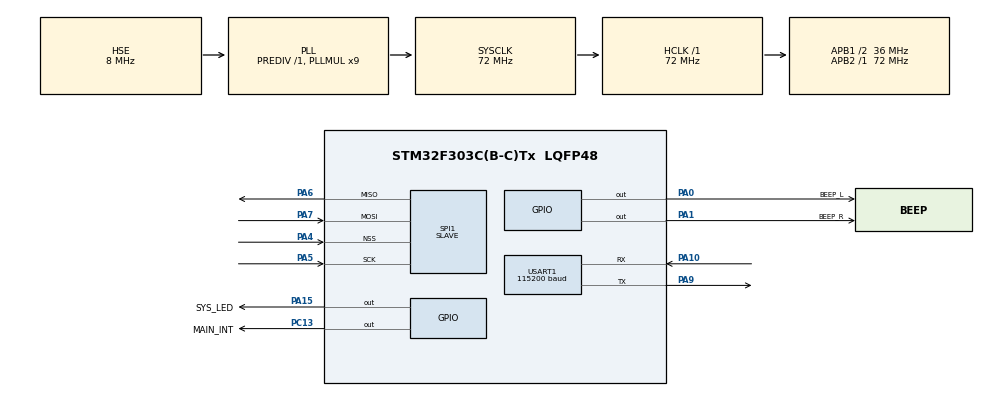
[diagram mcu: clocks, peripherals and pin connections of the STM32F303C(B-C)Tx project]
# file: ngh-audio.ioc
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Mcu.Family=STM32F3
Mcu.Name=STM32F303C(B-C)Tx
Mcu.Package=LQFP48
NVIC.PriorityGroup=NVIC_PRIORITYGROUP_4
NVIC.SPI1_IRQn=true\:1\:0\:true\:false\:true\:true
NVIC.TIM2_IRQn=true\:0\:0\:false\:false\:true\:true
PA0.GPIO_Label=BEEP_L
PA0.Signal=GPIO_Output
PA1.GPIO_Label=BEEP_R
PA1.Signal=GPIO_Output
PA10.GPIO_PuPd=GPIO_PULLUP
PA10.Mode=Multiprocessor_communication
PA10.Signal=USART1_RX
PA13.Mode=Serial_Wire
PA13.Signal=SYS_JTMS-SWDIO
PA14.Mode=Serial_Wire
PA14.Signal=SYS_JTCK-SWCLK
PA15.GPIO_Label=SYS_LED
PA15.GPIO_Speed=GPIO_SPEED_FREQ_HIGH
PA15.Signal=GPIO_Output
PA4.Mode=NSS_Signal_Hard_Input
PA4.Signal=SPI1_NSS
PA5.Mode=Full_Duplex_Slave
PA5.Signal=SPI1_SCK
PA6.Mode=Full_Duplex_Slave
PA6.Signal=SPI1_MISO
PA7.Mode=Full_Duplex_Slave
PA7.Signal=SPI1_MOSI
PA9.GPIO_PuPd=GPIO_PULLUP
PA9.Mode=Multiprocessor_communication
PA9.Signal=USART1_TX
PC13.GPIO_Label=MAIN_INT
PC13.GPIO_Speed=GPIO_SPEED_FREQ_LOW
PC13.PinState=GPIO_PIN_SET
PC13.Signal=GPIO_Output
PF0-OSC_IN.Mode=HSE-External-Oscillator
PF0-OSC_IN.Signal=RCC_OSC_IN
PF1-OSC_OUT.Mode=HSE-External-Oscillator
PF1-OSC_OUT.Signal=RCC_OSC_OUT
ProjectManager.HeapSize=0x200
ProjectManager.StackSize=0x400
ProjectManager.TargetToolchain=SW4STM32
RCC.AHBFreq_Value=72000000
RCC.APB1CLKDivider=RCC_HCLK_DIV2
RCC.APB1Freq_Value=36000000
RCC.APB1TimFreq_Value=72000000
RCC.APB2Freq_Value=72000000
RCC.APB2TimFreq_Value=72000000
RCC.CortexFreq_Value=72000000
RCC.HCLKFreq_Value=72000000
RCC.HSE_VALUE=8000000
RCC.HSI_VALUE=8000000
RCC.LSE_VALUE=32768
RCC.PLLMUL=RCC_PLL_MUL9
RCC.PLLSourceVirtual=RCC_PLLSOURCE_HSE
RCC.SYSCLKFreq_VALUE=72000000
RCC.SYSCLKSourceVirtual=RCC_SYSCLKSOURCE_PLLCLK
RCC.USBFreq_Value=72000000
SPI1.DataSize=SPI_DATASIZE_8BIT
SPI1.Direction=SPI_DIRECTION_2LINES
SPI1.Mode=SPI_MODE_SLAVE
SPI1.VirtualNSS=VM_NSSHARD
SPI1.VirtualType=VM_SLAVE
TIM2.Period=99
TIM2.Prescaler=72
USART1.BaudRate=115200
USART1.VirtualMode-Multiprocessor_communication=VM_ASYNC
VP_TIM2_VS_ClockSourceINT.Mode=Internal
board=custom

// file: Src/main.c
/* USER CODE BEGIN Header */
/**
  ******************************************************************************
  * @file           : main.c
  * @brief          : Main program body
  ******************************************************************************
  ** This notice applies to any and all portions of this file
  * that are not between comment pairs USER CODE BEGIN and
  * USER CODE END. Other portions of this file, whether
  * inserted by the user or by software development tools
  * are owned by their respective copyright owners.
  *
  * COPYRIGHT(c) 2018 STMicroelectronics
  *
  * Redistribution and use in source and binary forms, with or without modification,
  * are permitted provided that the following conditions are met:
  *   1. Redistributions of source code must retain the above copyright notice,
  *      this list of conditions and the following disclaimer.
  *   2. Redistributions in binary form must reproduce the above copyright notice,
  *      this list of conditions and the following disclaimer in the documentation
  *      and/or other materials provided with the distribution.
  *   3. Neither the name of STMicroelectronics nor the names of its contributors
  *      may be used to endorse or promote products derived from this software
  *      without specific prior written permission.
  *
  * THIS SOFTWARE IS PROVIDED BY THE COPYRIGHT HOLDERS AND CONTRIBUTORS "AS IS"
  * AND ANY EXPRESS OR IMPLIED WARRANTIES, INCLUDING, BUT NOT LIMITED TO, THE
  * IMPLIED WARRANTIES OF MERCHANTABILITY AND FITNESS FOR A PARTICULAR PURPOSE ARE
  * DISCLAIMED. IN NO EVENT SHALL THE COPYRIGHT HOLDER OR CONTRIBUTORS BE LIABLE
  * FOR ANY DIRECT, INDIRECT, INCIDENTAL, SPECIAL, EXEMPLARY, OR CONSEQUENTIAL
  * DAMAGES (INCLUDING, BUT NOT LIMITED TO, PROCUREMENT OF SUBSTITUTE GOODS OR
  * SERVICES; LOSS OF USE, DATA, OR PROFITS; OR BUSINESS INTERRUPTION) HOWEVER
  * CAUSED AND ON ANY THEORY OF LIABILITY, WHETHER IN CONTRACT, STRICT LIABILITY,
  * OR TORT (INCLUDING NEGLIGENCE OR OTHERWISE) ARISING IN ANY WAY OUT OF THE USE
  * OF THIS SOFTWARE, EVEN IF ADVISED OF THE POSSIBILITY OF SUCH DAMAGE.
  *
  ******************************************************************************
  */
/* USER CODE END Header */

#include "main.h"

SPI_HandleTypeDef hspi1;

TIM_HandleTypeDef htim2;

UART_HandleTypeDef huart1;

void SystemClock_Config(void);
static void MX_GPIO_Init(void);
static void MX_SPI1_Init(void);
static void MX_USART1_UART_Init(void);
static void MX_TIM2_Init(void);

/* USER CODE BEGIN 0 */
__IO uint32_t _cnt = 0, _max = 5000;
void TIM2_IRQ_Callback() {
	if (_cnt < _max) _cnt += 1;
	else {
		_cnt = 0;
		HAL_GPIO_TogglePin(SYS_LED_GPIO_Port, SYS_LED_Pin);
	}
}
/* USER CODE END 0 */

int main(void)
{

  /* MCU Configuration--------------------------------------------------------*/

  /* Reset of all peripherals, Initializes the Flash interface and the Systick. */
  HAL_Init();

  /* Configure the system clock */
  SystemClock_Config();

  /* Initialize all configured peripherals */
  MX_GPIO_Init();
  MX_SPI1_Init();
  MX_USART1_UART_Init();
  MX_TIM2_Init();
  /* USER CODE BEGIN 2 */
  HAL_TIM_Base_Start_IT(&htim2);
  /* USER CODE END 2 */

  /* Infinite loop */
  while (1)
  {

  }
}

void SystemClock_Config(void)
{
  RCC_OscInitTypeDef RCC_OscInitStruct = {0};
  RCC_ClkInitTypeDef RCC_ClkInitStruct = {0};
  RCC_PeriphCLKInitTypeDef PeriphClkInit = {0};

  /**Initializes the CPU, AHB and APB busses clocks
  */
  RCC_OscInitStruct.OscillatorType = RCC_OSCILLATORTYPE_HSE;
  RCC_OscInitStruct.HSEState = RCC_HSE_ON;
  RCC_OscInitStruct.HSEPredivValue = RCC_HSE_PREDIV_DIV1;
  RCC_OscInitStruct.HSIState = RCC_HSI_ON;
  RCC_OscInitStruct.PLL.PLLState = RCC_PLL_ON;
  RCC_OscInitStruct.PLL.PLLSource = RCC_PLLSOURCE_HSE;
  RCC_OscInitStruct.PLL.PLLMUL = RCC_PLL_MUL9;
  if (HAL_RCC_OscConfig(&RCC_OscInitStruct) != HAL_OK)
  {
    Error_Handler();
  }
  /**Initializes the CPU, AHB and APB busses clocks
  */
  RCC_ClkInitStruct.ClockType = RCC_CLOCKTYPE_HCLK|RCC_CLOCKTYPE_SYSCLK
                              |RCC_CLOCKTYPE_PCLK1|RCC_CLOCKTYPE_PCLK2;
  RCC_ClkInitStruct.SYSCLKSource = RCC_SYSCLKSOURCE_PLLCLK;
  RCC_ClkInitStruct.AHBCLKDivider = RCC_SYSCLK_DIV1;
  RCC_ClkInitStruct.APB1CLKDivider = RCC_HCLK_DIV2;
  RCC_ClkInitStruct.APB2CLKDivider = RCC_HCLK_DIV1;

  if (HAL_RCC_ClockConfig(&RCC_ClkInitStruct, FLASH_LATENCY_2) != HAL_OK)
  {
    Error_Handler();
  }
  PeriphClkInit.PeriphClockSelection = RCC_PERIPHCLK_USART1;
  PeriphClkInit.Usart1ClockSelection = RCC_USART1CLKSOURCE_PCLK2;
  if (HAL_RCCEx_PeriphCLKConfig(&PeriphClkInit) != HAL_OK)
  {
    Error_Handler();
  }
}

static void MX_SPI1_Init(void)
{

  /* SPI1 parameter configuration*/
  hspi1.Instance = SPI1;
  hspi1.Init.Mode = SPI_MODE_SLAVE;
  hspi1.Init.Direction = SPI_DIRECTION_2LINES;
  hspi1.Init.DataSize = SPI_DATASIZE_8BIT;
  hspi1.Init.CLKPolarity = SPI_POLARITY_LOW;
  hspi1.Init.CLKPhase = SPI_PHASE_1EDGE;
  hspi1.Init.NSS = SPI_NSS_HARD_INPUT;
  hspi1.Init.FirstBit = SPI_FIRSTBIT_MSB;
  hspi1.Init.TIMode = SPI_TIMODE_DISABLE;
  hspi1.Init.CRCCalculation = SPI_CRCCALCULATION_DISABLE;
  hspi1.Init.CRCPolynomial = 7;
  hspi1.Init.CRCLength = SPI_CRC_LENGTH_DATASIZE;
  hspi1.Init.NSSPMode = SPI_NSS_PULSE_DISABLE;
  if (HAL_SPI_Init(&hspi1) != HAL_OK)
  {
    Error_Handler();
  }

}

static void MX_TIM2_Init(void)
{

  TIM_ClockConfigTypeDef sClockSourceConfig = {0};
  TIM_MasterConfigTypeDef sMasterConfig = {0};

  htim2.Instance = TIM2;
  htim2.Init.Prescaler = 72;
  htim2.Init.CounterMode = TIM_COUNTERMODE_UP;
  htim2.Init.Period = 99;
  htim2.Init.ClockDivision = TIM_CLOCKDIVISION_DIV1;
  htim2.Init.AutoReloadPreload = TIM_AUTORELOAD_PRELOAD_DISABLE;
  if (HAL_TIM_Base_Init(&htim2) != HAL_OK)
  {
    Error_Handler();
  }
  sClockSourceConfig.ClockSource = TIM_CLOCKSOURCE_INTERNAL;
  if (HAL_TIM_ConfigClockSource(&htim2, &sClockSourceConfig) != HAL_OK)
  {
    Error_Handler();
  }
  sMasterConfig.MasterOutputTrigger = TIM_TRGO_RESET;
  sMasterConfig.MasterSlaveMode = TIM_MASTERSLAVEMODE_DISABLE;
  if (HAL_TIMEx_MasterConfigSynchronization(&htim2, &sMasterConfig) != HAL_OK)
  {
    Error_Handler();
  }

}

static void MX_USART1_UART_Init(void)
{

  huart1.Instance = USART1;
  huart1.Init.BaudRate = 115200;
  huart1.Init.WordLength = UART_WORDLENGTH_8B;
  huart1.Init.StopBits = UART_STOPBITS_1;
  huart1.Init.Parity = UART_PARITY_NONE;
  huart1.Init.Mode = UART_MODE_TX_RX;
  huart1.Init.HwFlowCtl = UART_HWCONTROL_NONE;
  huart1.Init.OverSampling = UART_OVERSAMPLING_16;
  huart1.Init.OneBitSampling = UART_ONE_BIT_SAMPLE_DISABLE;
  huart1.AdvancedInit.AdvFeatureInit = UART_ADVFEATURE_NO_INIT;
  if (HAL_MultiProcessor_Init(&huart1, 0, UART_WAKEUPMETHOD_IDLELINE) != HAL_OK)
  {
    Error_Handler();
  }

}

static void MX_GPIO_Init(void)
{
  GPIO_InitTypeDef GPIO_InitStruct = {0};

  /* GPIO Ports Clock Enable */
  __HAL_RCC_GPIOC_CLK_ENABLE();
  __HAL_RCC_GPIOF_CLK_ENABLE();
  __HAL_RCC_GPIOA_CLK_ENABLE();

  /*Configure GPIO pin Output Level */
  HAL_GPIO_WritePin(MAIN_INT_GPIO_Port, MAIN_INT_Pin, GPIO_PIN_SET);

  /*Configure GPIO pin Output Level */
  HAL_GPIO_WritePin(GPIOA, BEEP_L_Pin|BEEP_R_Pin|SYS_LED_Pin, GPIO_PIN_RESET);

  /*Configure GPIO pin : MAIN_INT_Pin */
  GPIO_InitStruct.Pin = MAIN_INT_Pin;
  GPIO_InitStruct.Mode = GPIO_MODE_OUTPUT_PP;
  GPIO_InitStruct.Pull = GPIO_NOPULL;
  GPIO_InitStruct.Speed = GPIO_SPEED_FREQ_LOW;
  HAL_GPIO_Init(MAIN_INT_GPIO_Port, &GPIO_InitStruct);

  /*Configure GPIO pins : BEEP_L_Pin BEEP_R_Pin */
  GPIO_InitStruct.Pin = BEEP_L_Pin|BEEP_R_Pin;
  GPIO_InitStruct.Mode = GPIO_MODE_OUTPUT_PP;
  GPIO_InitStruct.Pull = GPIO_NOPULL;
  GPIO_InitStruct.Speed = GPIO_SPEED_FREQ_LOW;
  HAL_GPIO_Init(GPIOA, &GPIO_InitStruct);

  /*Configure GPIO pin : SYS_LED_Pin */
  GPIO_InitStruct.Pin = SYS_LED_Pin;
  GPIO_InitStruct.Mode = GPIO_MODE_OUTPUT_PP;
  GPIO_InitStruct.Pull = GPIO_NOPULL;
  GPIO_InitStruct.Speed = GPIO_SPEED_FREQ_HIGH;
  HAL_GPIO_Init(SYS_LED_GPIO_Port, &GPIO_InitStruct);

}

void Error_Handler(void)
{
}

/************************ (C) COPYRIGHT STMicroelectronics *****END OF FILE****/
